# HSM_TC3xx register map
Vendor: Infineon; Series: AURIX TC3xx; File version: 2.0
CPU: CM3 r2p0, little endian, MPU, no FPU, 3 interrupt priority bits
Registers are 32-bit, read-write, no defined reset value unless marked. A register's access mark holds for its fields unless they carry their own. Offsets are from the block's base; [hi:lo] are bit positions; {n}, {i} and the like mark numbered series; 'fields as' and 'values as' point back to an identical list.

## HSM_SCNSCB — Cortex-M3 system control, not in the SCB (ARMv7-M).
Base 0xE000E000
0x04 ICTR ro — Interrupt Controller Type Register
  [3:0] INTLINESNUM — Number of interrupt lines / 32 - 1
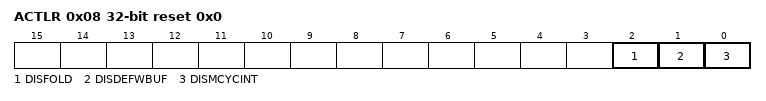
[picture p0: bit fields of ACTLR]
0x08 ACTLR reset 0x0 — Auxiliary Control Register
  [2] DISFOLD — Disable IT folding
  [1] DISDEFWBUF — Disable write buffer for default memory map
  [0] DISMCYCINT — Disable interruption of multi-cycle instructions

## HSM_SYSTICK — Cortex-M3 SysTick timer. Reference clock: SPB clock / 16. Suspended in HALT mode (HSM TS 2.2.2).
Base 0xE000E010
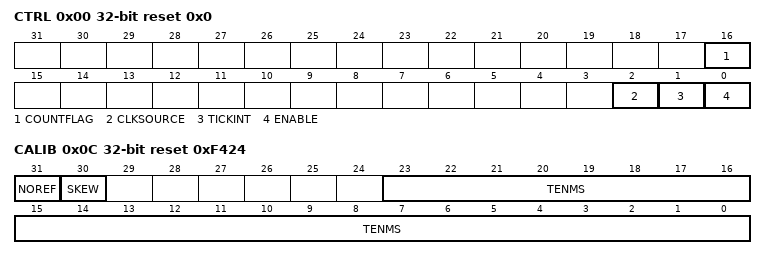
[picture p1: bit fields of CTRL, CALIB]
0x00 CTRL reset 0x0 — SysTick Control and Status Register
  [16] COUNTFLAG ro — Counted to 0 since last read (cleared on read)
  [2] CLKSOURCE — Clock source
    0=REF (Reference clock (SPB/16)); 1=CORE (HSM system clock)
  [1] TICKINT — SysTick exception request enable
  [0] ENABLE — Counter enable
0x04 LOAD — SysTick Reload Value Register
  [23:0] RELOAD — Reload value
0x08 VAL — SysTick Current Value Register (any write clears it)
  [23:0] CURRENT — Current counter value
0x0C CALIB ro reset 0xF424 (reset mask 0xFFFFFF) — SysTick Calibration Value Register (62500 = 10 ms at 100 MHz SPB)
  [31] NOREF — No reference clock
  [30] SKEW — TENMS not exact
  [23:0] TENMS — Reload value for 10 ms

## HSM_NVIC — Cortex-M3 NVIC: 10 interrupts, 8 priority levels (3 bits, 7:5 of each priority byte). HSM TS 2.3.
Base 0xE000E100
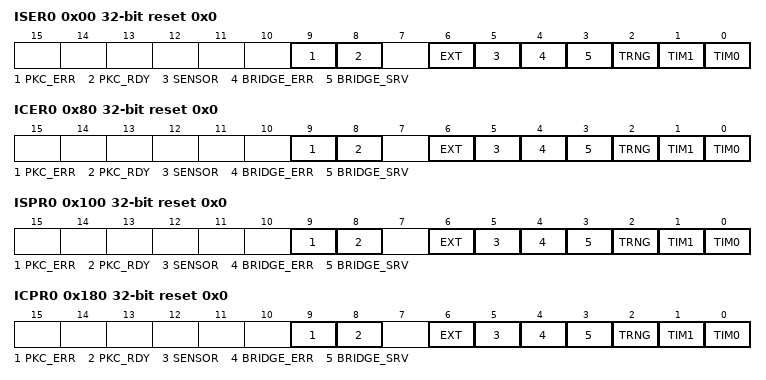
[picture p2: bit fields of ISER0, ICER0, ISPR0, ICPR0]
0x00 ISER0 reset 0x0 write-1-sets — Interrupt Set-Enable Register
  [9] PKC_ERR — PKC error interrupt (IRQ 9)
  [8] PKC_RDY — PKC ready interrupt (IRQ 8)
  [6] EXT — External peripheral interrupt (IRQ 6)
  [5] SENSOR — Sensor interrupt (IRQ 5)
  [4] BRIDGE_ERR — Bridge error interrupt (IRQ 4)
  [3] BRIDGE_SRV — Bridge service interrupt (IRQ 3)
  [2] TRNG — TRNG interrupt (IRQ 2)
  [1] TIM1 — Timer 1 interrupt (IRQ 1)
  [0] TIM0 — Timer 0 interrupt (IRQ 0)
0x80 ICER0 reset 0x0 write-1-clears — Interrupt Clear-Enable Register (reads the enable state)
  fields as ISER0
0x100 ISPR0 reset 0x0 write-1-sets — Interrupt Set-Pending Register
  fields as ISER0
0x180 ICPR0 reset 0x0 write-1-clears — Interrupt Clear-Pending Register (reads the pending state)
  fields as ISER0
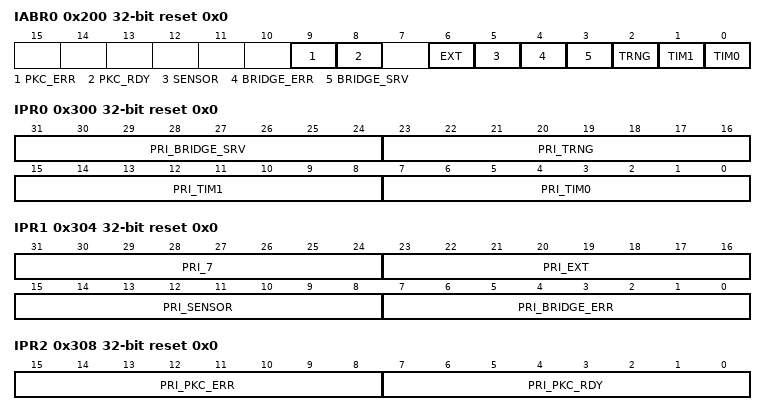
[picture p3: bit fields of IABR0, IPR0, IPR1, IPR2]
0x200 IABR0 ro reset 0x0 — Interrupt Active Bit Register
  fields as ISER0
0x300 IPR0 reset 0x0 — Interrupt Priority Register 0
  [31:24] PRI_BRIDGE_SRV — Priority of IRQ 3
  [23:16] PRI_TRNG — Priority of IRQ 2
  [15:8] PRI_TIM1 — Priority of IRQ 1
  [7:0] PRI_TIM0 — Priority of IRQ 0 (bits 7:5 implemented)
0x304 IPR1 reset 0x0 — Interrupt Priority Register 1
  [31:24] PRI_7 — Priority of IRQ 7 (not connected)
  [23:16] PRI_EXT — Priority of IRQ 6
  [15:8] PRI_SENSOR — Priority of IRQ 5
  [7:0] PRI_BRIDGE_ERR — Priority of IRQ 4
0x308 IPR2 reset 0x0 — Interrupt Priority Register 2
  [15:8] PRI_PKC_ERR — Priority of IRQ 9
  [7:0] PRI_PKC_RDY — Priority of IRQ 8
0xE00 STIR wo — Software Trigger Interrupt Register
  [8:0] INTID — Interrupt to trigger

## HSM_MPU — Cortex-M3 memory protection unit, 8 regions (PMSAv7; C, S and TEX are ignored on the HSM, HSM TS 2.4).
Base 0xE000ED90
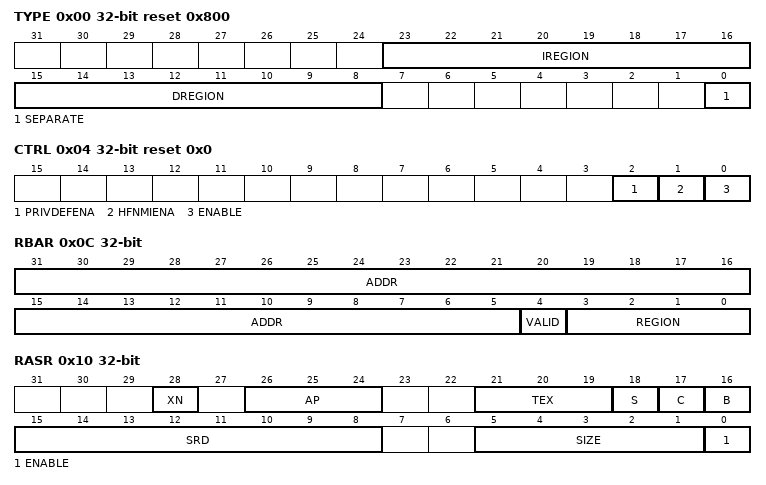
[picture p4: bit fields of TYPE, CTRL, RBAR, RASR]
0x00 TYPE ro reset 0x800 — MPU Type Register
  [23:16] IREGION — Instruction regions (0: unified)
  [15:8] DREGION — Number of regions
  [0] SEPARATE — Separate instruction/data maps
0x04 CTRL reset 0x0 — MPU Control Register
  [2] PRIVDEFENA — Default memory map for privileged accesses
  [1] HFNMIENA — MPU enabled in HardFault/NMI
  [0] ENABLE — MPU enable
0x08 RNR — MPU Region Number Register
  [7:0] REGION — Region shown in RBAR/RASR
0x0C RBAR — MPU Region Base Address Register
  [31:5] ADDR — Region base address
  [4] VALID — Write: use REGION instead of RNR. Reads as 0.
  [3:0] REGION — Region number
0x10 RASR — MPU Region Attribute and Size Register
  [28] XN — Execute never
  [26:24] AP — Access permissions
  [21:19] TEX — Type extension (ignored on the HSM)
  [18] S — Shareable (ignored)
  [17] C — Cacheable (ignored)
  [16] B — Bufferable
  [15:8] SRD — Subregion disable
  [5:1] SIZE — Region size 2^(SIZE+1)
  [0] ENABLE — Region enable
{0xC+8i} RBAR_A{i} (i=1..3) — Alias {i} of RBAR
  [31:0] RBAR — Same as RBAR
{0x10+8i} RASR_A{i} (i=1..3) — Alias {i} of RASR
  [31:0] RASR — Same as RASR
